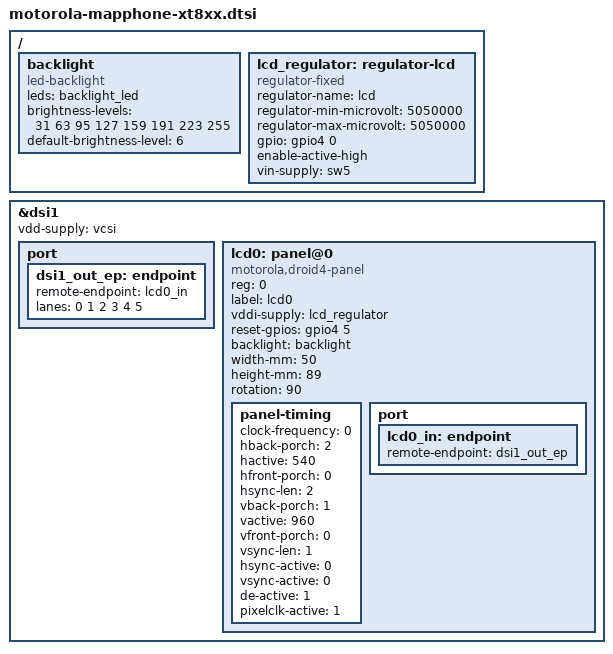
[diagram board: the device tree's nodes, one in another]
// SPDX-License-Identifier: GPL-2.0-only
/dts-v1/;

#include "motorola-mapphone-handset.dtsi"

/ {
	backlight: backlight {
		compatible = "led-backlight";

		leds = <&backlight_led>;
		brightness-levels = <31 63 95 127 159 191 223 255>;
		default-brightness-level = <6>;
	};

	/* LCD regulator from sw5 source */
	lcd_regulator: regulator-lcd {
		compatible = "regulator-fixed";
		regulator-name = "lcd";
		regulator-min-microvolt = <5050000>;
		regulator-max-microvolt = <5050000>;
		gpio = <&gpio4 0 GPIO_ACTIVE_HIGH>;	/* gpio96 */
		enable-active-high;
		vin-supply = <&sw5>;
	};
};

&dsi1 {
	status = "okay";
	vdd-supply = <&vcsi>;

	port {
		dsi1_out_ep: endpoint {
			remote-endpoint = <&lcd0_in>;
			lanes = <0 1 2 3 4 5>;
		};
	};

	lcd0: panel@0 {
		compatible = "motorola,droid4-panel", "panel-dsi-cm";
		reg = <0>;
		label = "lcd0";
		vddi-supply = <&lcd_regulator>;
		reset-gpios = <&gpio4 5 GPIO_ACTIVE_HIGH>;	/* gpio101 */
		backlight = <&backlight>;

		width-mm = <50>;
		height-mm = <89>;
		rotation = <90>;

		panel-timing {
			clock-frequency = <0>;		/* Calculated by dsi */

			hback-porch = <2>;
			hactive = <540>;
			hfront-porch = <0>;
			hsync-len = <2>;

			vback-porch = <1>;
			vactive = <960>;
			vfront-porch = <0>;
			vsync-len = <1>;

			hsync-active = <0>;
			vsync-active = <0>;
			de-active = <1>;
			pixelclk-active = <1>;
		};

		port {
			lcd0_in: endpoint {
				remote-endpoint = <&dsi1_out_ep>;
			};
		};
	};
};
